# N32H473 register map
Vendor: Nationstech Ltd.; File version: 1.0
Registers are 32-bit, read-write, reset 0x0 unless marked. A register's access mark holds for its fields unless they carry their own. Offsets are from the block's base; [hi:lo] are bit positions; {n}, {i} and the like mark numbered series.

## USART1
Base 0x40011C00
Same registers: USART2 0x40000C00, USART3 0x40001000, UART8 0x40001400, UART5 0x40006800, UART6 0x40012000, UART7 0x40012400, USART4 0x40012800
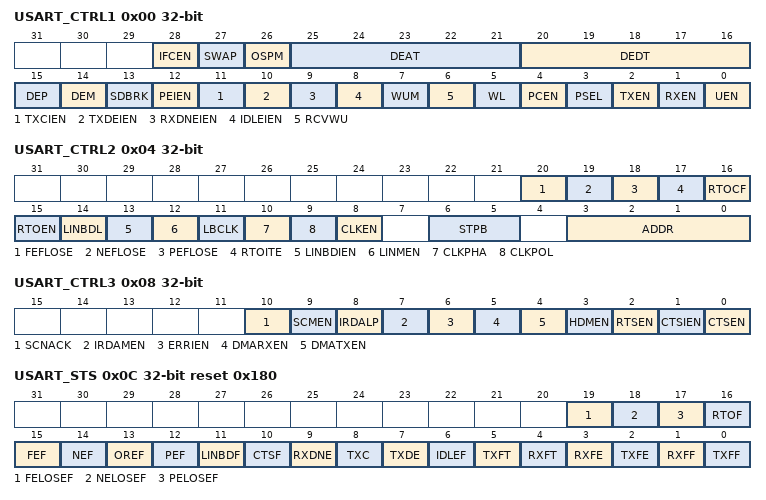
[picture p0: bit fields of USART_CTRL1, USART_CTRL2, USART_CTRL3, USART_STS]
0x00 USART_CTRL1
  [28] IFCEN, [27] SWAP, [26] OSPM, [25:21] DEAT, [20:16] DEDT, [15] DEP, [14] DEM, [13] SDBRK, [12] PEIEN, [11] TXCIEN, [10] TXDEIEN, [9] RXDNEIEN, [8] IDLEIEN, [7] WUM, [6] RCVWU, [5] WL, [4] PCEN, [3] PSEL, [2] TXEN, [1] RXEN, [0] UEN
0x04 USART_CTRL2
  [20] FEFLOSE, [19] NEFLOSE, [18] PEFLOSE, [17] RTOITE, [16] RTOCF, [15] RTOEN, [14] LINBDL, [13] LINBDIEN, [12] LINMEN, [11] LBCLK, [10] CLKPHA, [9] CLKPOL, [8] CLKEN, [6:5] STPB, [3:0] ADDR
0x08 USART_CTRL3
  [10] SCNACK, [9] SCMEN, [8] IRDALP, [7] IRDAMEN, [6] ERRIEN, [5] DMARXEN, [4] DMATXEN, [3] HDMEN, [2] RTSEN, [1] CTSIEN, [0] CTSEN
0x0C USART_STS reset 0x180
  [19] FELOSEF, [18] NELOSEF, [17] PELOSEF, [16] RTOF, [15] FEF, [14] NEF, [13] OREF, [12] PEF, [11] LINBDF, [10] CTSF, [9] RXDNE, [8] TXC, [7] TXDE, [6] IDLEF, [5] TXFT, [4] RXFT, [3] RXFE, [2] TXFE, [1] RXFF, [0] TXFF
0x10 USART_DAT
  [8:0] DATV
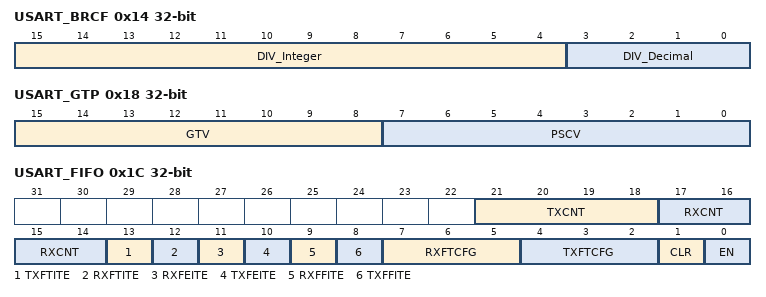
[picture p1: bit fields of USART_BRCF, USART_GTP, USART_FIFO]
0x14 USART_BRCF
  [15:4] DIV_Integer, [3:0] DIV_Decimal
0x18 USART_GTP
  [15:8] GTV, [7:0] PSCV
0x1C USART_FIFO
  [21:18] TXCNT, [17:14] RXCNT, [13] TXFTITE, [12] RXFTITE, [11] RXFEITE, [10] TXFEITE, [9] RXFFITE, [8] TXFFITE, [7:5] RXFTCFG, [4:2] TXFTCFG, [1] CLR, [0] EN
0x20 USART_IFW
  [15:0] WIDTH
0x24 USART_RTO
  [27:0] TIME

## ADC1
Base 0x4002B000
Same registers: ADC2 0x4002B400, ADC3 0x4002B800, ADC4 0x4002BC00
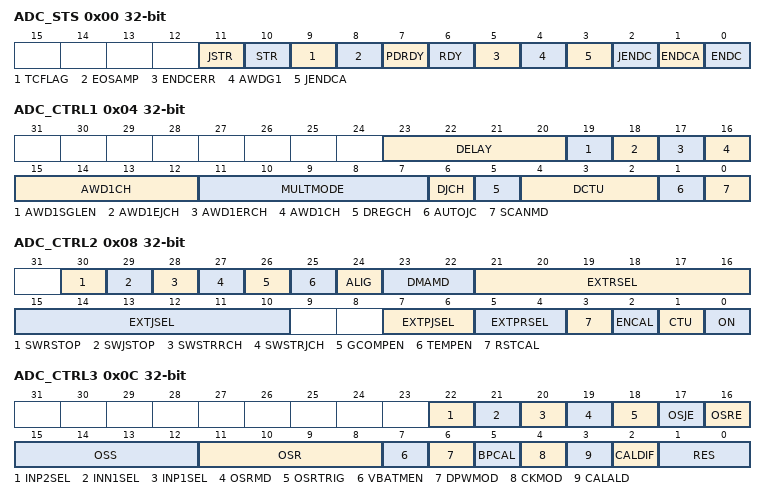
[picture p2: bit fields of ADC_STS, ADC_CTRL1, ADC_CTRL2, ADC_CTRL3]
0x00 ADC_STS
  [11] JSTR, [10] STR, [9] TCFLAG, [8] EOSAMP, [7] PDRDY, [6] RDY, [5] ENDCERR, [4] AWDG1, [3] JENDCA, [2] JENDC, [1] ENDCA, [0] ENDC
0x04 ADC_CTRL1
  [23:20] DELAY, [19] AWD1SGLEN, [18] AWD1EJCH, [17] AWD1ERCH, [16:12] AWD1CH, [11:7] MULTMODE, [6] DJCH, [5] DREGCH, [4:2] DCTU, [1] AUTOJC, [0] SCANMD
0x08 ADC_CTRL2
  [30] SWRSTOP, [29] SWJSTOP, [28] SWSTRRCH, [27] SWSTRJCH, [26] GCOMPEN, [25] TEMPEN, [24] ALIG, [23:22] DMAMD, [21:16] EXTRSEL, [15:10] EXTJSEL, [7:6] EXTPJSEL, [5:4] EXTPRSEL, [3] RSTCAL, [2] ENCAL, [1] CTU, [0] ON
0x0C ADC_CTRL3
  [22] INP2SEL, [21] INN1SEL, [20] INP1SEL, [19] OSRMD, [18] OSRTRIG, [17] OSJE, [16] OSRE, [15:12] OSS, [11:8] OSR, [7] VBATMEN, [6] DPWMOD, [5] BPCAL, [4] CKMOD, [3] CALALD, [2] CALDIF, [1:0] RES
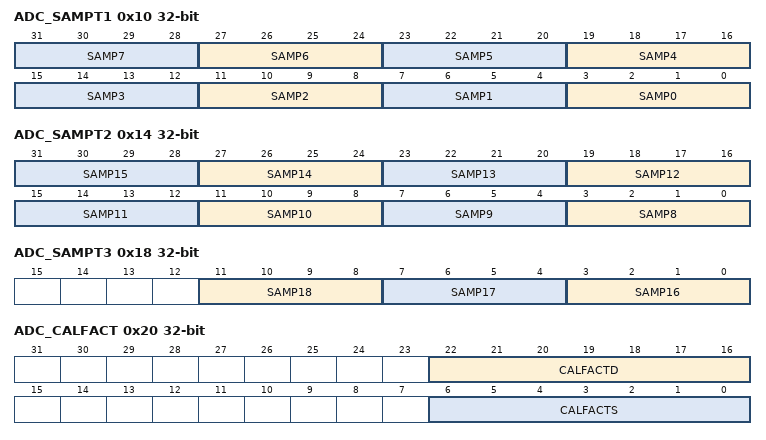
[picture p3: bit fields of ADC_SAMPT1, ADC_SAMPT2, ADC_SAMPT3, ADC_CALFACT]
0x10 ADC_SAMPT1
  [4n+3:4n] SAMP{n} (n=0..7)
0x14 ADC_SAMPT2
  [4n-29:4n-32] SAMP{n} (n=8..15)
0x18 ADC_SAMPT3
  [11:8] SAMP18, [7:4] SAMP17, [3:0] SAMP16
0x1C ADC_DIFSEL
  [18:1] DIFSEL
0x20 ADC_CALFACT
  [22:16] CALFACTD, [6:0] CALFACTS
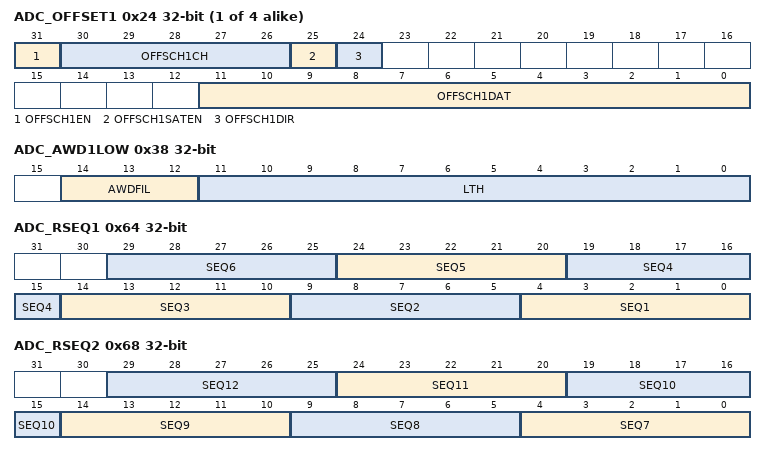
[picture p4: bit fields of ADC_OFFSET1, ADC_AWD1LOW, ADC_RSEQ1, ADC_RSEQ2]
{0x20+4i} ADC_OFFSET{i} (i=1..4)
  [31] OFFSCH{i}EN, [30:26] OFFSCH{i}CH, [25] OFFSCH{i}SATEN, [24] OFFSCH{i}DIR, [11:0] OFFSCH{i}DAT
{0x2C+8i} ADC_AWD{i}HIGH reset 0xFFF (i=1..3)
  [11:0] HTH
0x38 ADC_AWD1LOW
  [14:12] AWDFIL, [11:0] LTH
0x40 ADC_AWD2LOW
  [11:0] LTH
0x48 ADC_AWD3LOW
  [11:0] LTH
0x4C ADC_AWD2EN
  [18:0] AWD2EN
0x50 ADC_AWD3EN
  [18:0] AWD3EN
0x54 ADC_AWD2INTEN
  [18:0] AWD2INTEN
0x58 ADC_AWD3INTEN
  [18:0] AWD3INTEN
0x5C ADC_AWD2STS
  [18:0] AWD2FLAG
0x60 ADC_AWD3STS
  [18:0] AWD2FLAG
0x64 ADC_RSEQ1
  [5n-1:5n-5] SEQ{n} (n=1..6)
0x68 ADC_RSEQ2
  [5n-31:5n-35] SEQ{n} (n=7..12)
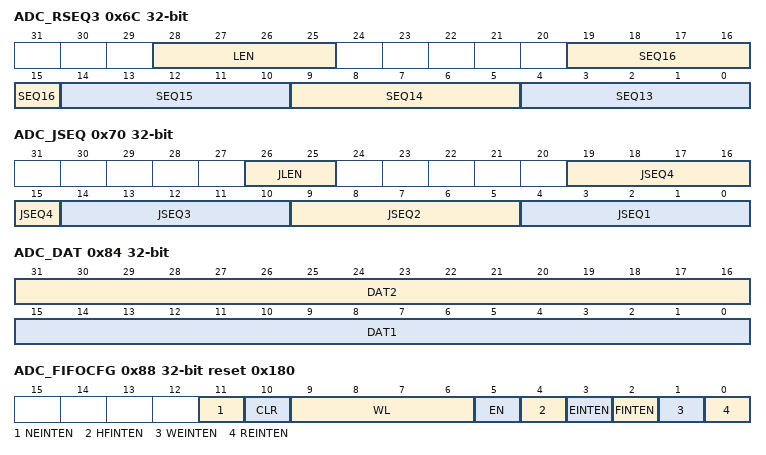
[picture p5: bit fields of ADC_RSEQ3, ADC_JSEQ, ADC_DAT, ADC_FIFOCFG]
0x6C ADC_RSEQ3
  [28:25] LEN, [5n-61:5n-65] SEQ{n} (n=13..16)
0x70 ADC_JSEQ
  [26:25] JLEN, [5n-1:5n-5] JSEQ{n} (n=1..4)
{0x70+4i} ADC_JDAT{i} (i=1..4)
  [15:0] JDAT
0x84 ADC_DAT
  [31:16] DAT2, [15:0] DAT1
0x88 ADC_FIFOCFG reset 0x180
  [11] NEINTEN, [10] CLR, [9:6] WL, [5] EN, [4] HFINTEN, [3] EINTEN, [2] FINTEN, [1] WEINTEN, [0] REINTEN
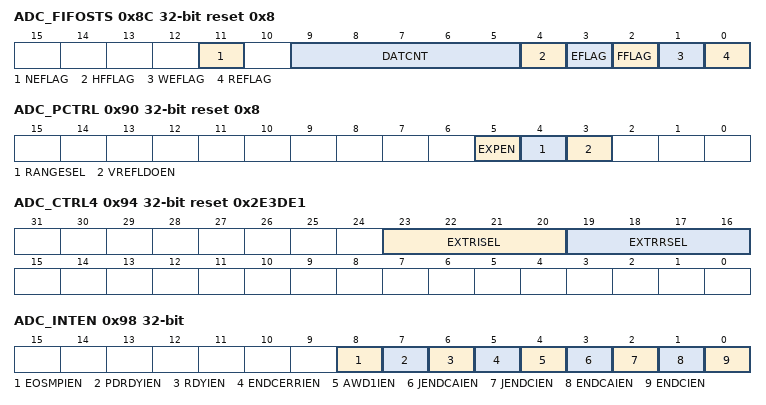
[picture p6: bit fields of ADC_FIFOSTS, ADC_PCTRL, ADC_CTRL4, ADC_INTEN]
0x8C ADC_FIFOSTS reset 0x8
  [11] NEFLAG, [9:5] DATCNT, [4] HFFLAG, [3] EFLAG, [2] FFLAG, [1] WEFLAG, [0] REFLAG
0x90 ADC_PCTRL reset 0x8
  [5] EXPEN, [4] RANGESEL, [3] VREFLDOEN
0x94 ADC_CTRL4 reset 0x2E3DE1
  [23:20] EXTRISEL, [19:16] EXTRRSEL
0x98 ADC_INTEN
  [8] EOSMPIEN, [7] PDRDYIEN, [6] RDYIEN, [5] ENDCERRIEN, [4] AWD1IEN, [3] JENDCAIEN, [2] JENDCIEN, [1] ENDCAIEN, [0] ENDCIEN
0x9C ADC_GCOMP
  [13:0] GCOMPDAT
